# ipro6s register map
Vendor: intelpro; Series: IPRO6S
CPU: ipro6s, little endian
Registers are 32-bit, read-write, reset 0x0 unless marked. A register's access mark holds for its fields unless they carry their own. Offsets are from the block's base; [hi:lo] are bit positions; {n}, {i} and the like mark numbered series.

## EF_DATA_0
Base 0x3000C000
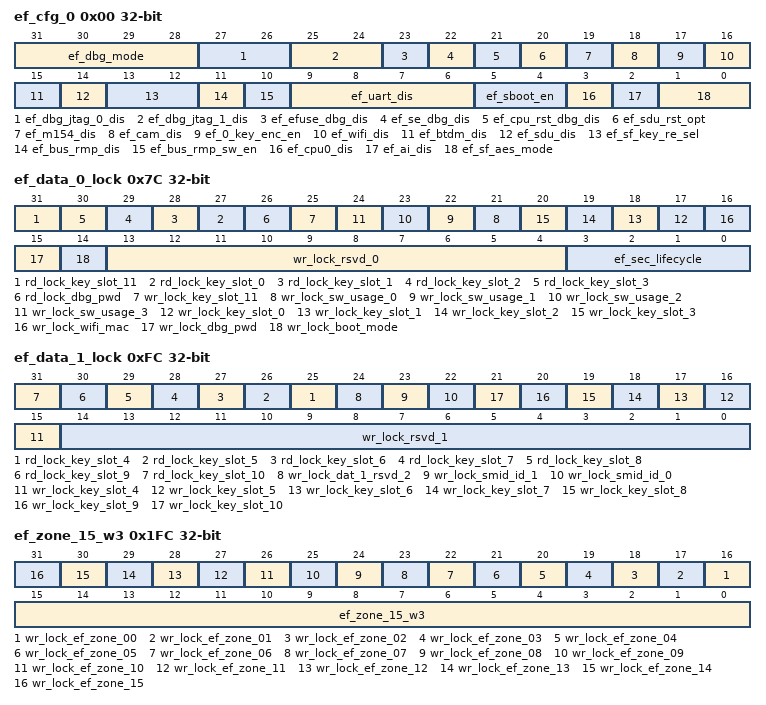
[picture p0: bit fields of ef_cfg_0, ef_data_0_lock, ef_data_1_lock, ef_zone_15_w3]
0x00 ef_cfg_0
  [31:28] ef_dbg_mode — 4'b0000:open mode 4'b0001:password mode 4'b0010:password mode 4'b0011:password mode 4'b0100:authentication mode 4'b1000:authentication mode 4'b1100:authentication mode others:close mode
  [27:26] ef_dbg_jtag_0_dis — 2'b00:enable JTAG port 0 others:disable JTAG port 0
  [25:24] ef_dbg_jtag_1_dis — 2'b00:enable JTAG port 1 others:disable JTAG port 1
  [23] ef_efuse_dbg_dis — 2'b00:enable eFuse manual mode others:disable eFuse manual mode
  [22] ef_se_dbg_dis — 2'b00:unprotected Others:disable secure engine debug mode
  [21] ef_cpu_rst_dbg_dis — 2'b00:unprotected Others:disable cpu reset debug mode
  [20] ef_sdu_rst_opt — sdu reset option: 0:hreset_n 1:pwronrst_n
  [19] ef_m154_dis — 1:disable m154
  [18] ef_cam_dis — 1:disable camera
  [17] ef_0_key_enc_en — 2'b00:disable efuse 0 key slot and debug port password encryption Others:enable efuse 0 key slot and debug port password encryption
  [16] ef_wifi_dis — 1:disable wifi
  [15] ef_btdm_dis — 1:disable btdm
  [14] ef_sdu_dis — 1:disable sdu
  [13:12] ef_sf_key_re_sel — when ef_sf_aes_mode=1 (AES-128) 2'b00:sf_aes_key_0 select key slot 2, sf_aes_key_1 select key slot 3 2'b01:sf_aes_key_0 select key slot 4, sf_aes_key_1 select key slot 5 2'b10:sf_aes_key_0 select key slot 2, sf_aes_key_1 select key slot 2 2'b11:sf_aes_key_0 select key slot 2, sf_aes_key_1 select key slot 3 when ef_sf_aes_mode=2/3 (AES-192/AES-256) 2'b10:sf_aes_key_0 select {ef_key_slot_3,ef_key_slot_2}, sf_aes_key_1 select {ef_key_slot_3,ef_key_slot_2}
  [11] ef_bus_rmp_dis — 1:disable
  [10] ef_bus_rmp_sw_en — 1:enable
  [9:6] ef_uart_dis — [9]1:disable uart3 [8]1:disable uart2 [7]1:disable uart1 [6]1:disable uart0
  [5:4] ef_sboot_en — 4'b0000:secure boot disable others:secure boot enable
  [3] ef_cpu0_dis — 1:disable cpu0
  [2] ef_ai_dis — 1:disable ai
  [1:0] ef_sf_aes_mode — 2'b00:plaintext 2'b01:AES-128 2'b10:AES-192 2'b11:AES-256
0x04 ef_dbg_pwd_low
  [31:0] ef_dbg_pwd_low — debug port password[31:0]
0x08 ef_dbg_pwd_high
  [31:0] ef_dbg_pwd_high — debug port password[63:32]
0x0C ef_dbg_pwd2_low
  [31:0] ef_dbg_pwd2_low — debug port password[95:64]
0x10 ef_dbg_pwd2_high
  [31:0] ef_dbg_pwd2_high — debug port password[127:96]
0x14 ef_wifi_mac_low
  [31:0] ef_wifi_mac_low — MAC address[31:0]
0x18 ef_wifi_mac_high
  [31:0] ef_wifi_mac_high — MAC address[63:32]
{0x1C+0x10*i} ef_key_slot_{i}_w0 (i=0..3)
  [31:0] ef_key_slot_{i}_w0 — AES key slot {i}
{0x20+0x10*i} ef_key_slot_{i}_w1 (i=0..3)
  [31:0] ef_key_slot_{i}_w1 — AES key slot {i}
{0x24+0x10*i} ef_key_slot_{i}_w2 (i=0..3)
  [31:0] ef_key_slot_{i}_w2 — AES key slot {i}
{0x28+0x10*i} ef_key_slot_{i}_w3 (i=0..3)
  [31:0] ef_key_slot_{i}_w3 — AES key slot {i}
{0x5C+4i} ef_sw_usage_{i} (i=0..3)
0x6C ef_key_slot_11_w0
  [31:0] ef_key_slot_11_w0 — AES key slot 11
0x70 ef_key_slot_11_w1
  [31:0] ef_key_slot_11_w1 — AES key slot 11
0x74 ef_key_slot_11_w2
  [31:0] ef_key_slot_11_w2 — AES key slot 11
0x78 ef_key_slot_11_w3
  [31:0] ef_key_slot_11_w3 — AES key slot 11
0x7C ef_data_0_lock
  [31] rd_lock_key_slot_11
  [n+27] rd_lock_key_slot_{n} (n=0..3)
  [26] rd_lock_dbg_pwd
  [25] wr_lock_key_slot_11
  [n+21] wr_lock_sw_usage_{n} (n=0..3)
  [n+17] wr_lock_key_slot_{n} (n=0..3)
  [16] wr_lock_wifi_mac
  [15] wr_lock_dbg_pwd
  [14] wr_lock_boot_mode
  [13:4] wr_lock_rsvd_0
  [3:0] ef_sec_lifecycle — 4'b0000:initial state 4'b0001:provisioning state 4'b0011:reserved state 4'b0111:secure state: enable sboot, disable debug signals from secure module 4'b1111:decommissioned state: zerorize all keys, disable all debug ports
{0x40+0x10*i} ef_key_slot_{i}_w0 (i=4..10)
  [31:0] ef_key_slot_{i}_w0 — AES key slot {i}
{0x44+0x10*i} ef_key_slot_{i}_w1 (i=4..10)
  [31:0] ef_key_slot_{i}_w1 — AES key slot {i}
{0x48+0x10*i} ef_key_slot_{i}_w2 (i=4..10)
  [31:0] ef_key_slot_{i}_w2 — AES key slot {i}
{0x4C+0x10*i} ef_key_slot_{i}_w3 (i=4..10)
  [31:0] ef_key_slot_{i}_w3 — AES key slot {i}
0xF0 ef_smid_id_0
0xF4 ef_smid_id_1
0xF8 ef_dat_1_rsvd_2
0xFC ef_data_1_lock
  [n+21] rd_lock_key_slot_{n} (n=4..10), [24] wr_lock_dat_1_rsvd_2, [23] wr_lock_smid_id_1, [22] wr_lock_smid_id_0, [n+11] wr_lock_key_slot_{n} (n=4..10), [14:0] wr_lock_rsvd_1
{0x100+0x10*i} ef_zone_{i:02}_w0 reset not defined (i=0..15)
{0x104+0x10*i} ef_zone_{i:02}_w1 reset not defined (i=0..15)
{0x108+0x10*i} ef_zone_{i:02}_w2 reset not defined (i=0..15)
{0x10C+0x10*i} ef_zone_{i:02}_w3 reset not defined (i=0..14)
0x1FC ef_zone_15_w3
  [n+16] wr_lock_ef_zone_{n:02} (n=0..15), [15:0] ef_zone_15_w3
